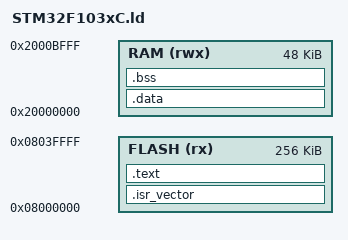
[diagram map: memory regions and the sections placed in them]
MEMORY
{
  FLASH (rx)  : ORIGIN = 0x08000000, LENGTH = 256K
  RAM   (rwx) : ORIGIN = 0x20000000, LENGTH = 48K
}

ENTRY(Reset_Handler)

_estack = ORIGIN(RAM) + LENGTH(RAM);

SECTIONS
{
  .isr_vector :
  {
    KEEP(*(.isr_vector))
  } > FLASH

  .text :
  {
    *(.text*)
    *(.rodata*)
    KEEP(*(.init))
    KEEP(*(.fini))

    . = ALIGN(4);
    __preinit_array_start = .;
    KEEP(*(.preinit_array*))
    __preinit_array_end = .;

    . = ALIGN(4);
    __init_array_start = .;
    KEEP(*(SORT(.init_array.*)))
    KEEP(*(.init_array*))
    __init_array_end = .;

    . = ALIGN(4);
    __fini_array_start = .;
    KEEP(*(SORT(.fini_array.*)))
    KEEP(*(.fini_array*))
    __fini_array_end = .;

    . = ALIGN(4);
    *(.ARM.extab* .gnu.linkonce.armextab.*)
    . = ALIGN(4);
    __exidx_start = .;
    *(.ARM.exidx* .gnu.linkonce.armexidx.*)
    __exidx_end = .;

    . = ALIGN(4);
    _etext = .;
    _sidata = _etext;
  } > FLASH

  .data : AT(_sidata)
  {
    . = ALIGN(4);
    _sdata = .;
    *(.data*)
    . = ALIGN(4);
    _edata = .;
  } > RAM

  .bss :
  {
    . = ALIGN(4);
    _sbss = .;
    *(.bss*)
    *(COMMON)
    . = ALIGN(4);
    _ebss = .;
    end = .;
    _end = .;
  } > RAM

  .ARM.attributes 0 : { *(.ARM.attributes) }
}
